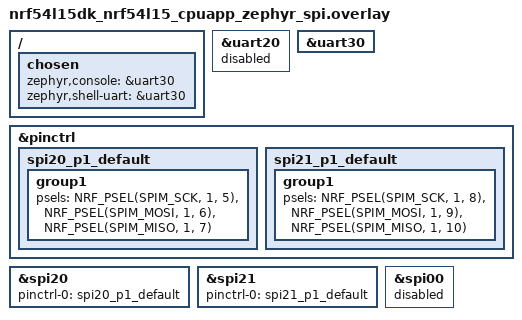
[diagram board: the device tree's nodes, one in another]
/*
 * Zephyr SPI test overlay: use Zephyr SPI driver on spi20 with P1.05 SCK, P1.06 MOSI.
 * Use with: west build -- -DCONF_FILE="prj.conf;prj_zephyr_spi.conf" -DDTC_OVERLAY_FILE=boards/nrf54l15dk_nrf54l15_cpuapp_zephyr_spi.overlay
 * Revert to nrfx by building without this overlay and without prj_zephyr_spi.conf.
 *
 * Slot 20: only one of SPI20/UARTE20/TWI20 can be enabled. Disable UART20 so SPI20 can be used.
 * Console was &uart20; point it to &uart30 so printk/console still work.
 */
/ {
	chosen {
		zephyr,console = &uart30;
		zephyr,shell-uart = &uart30;
	};
};

&uart20 {
	status = "disabled";
};

&uart30 {
	status = "okay";
};

&pinctrl {
	spi20_p1_default: spi20_p1_default {
		group1 {
			psels = <NRF_PSEL(SPIM_SCK, 1, 5)>,
				<NRF_PSEL(SPIM_MOSI, 1, 6)>,
				<NRF_PSEL(SPIM_MISO, 1, 7)>;
		};
	};

	spi21_p1_default: spi21_p1_default {
		group1 {
			/* Second SPI instance test on different P1 pins. */
			psels = <NRF_PSEL(SPIM_SCK, 1, 8)>,
				<NRF_PSEL(SPIM_MOSI, 1, 9)>,
				<NRF_PSEL(SPIM_MISO, 1, 10)>;
		};
	};
};

&spi20 {
	status = "okay";
	pinctrl-0 = <&spi20_p1_default>;
	pinctrl-names = "default";
};

&spi21 {
	status = "okay";
	pinctrl-0 = <&spi21_p1_default>;
	pinctrl-names = "default";
};

/* Slot 00: avoid conflict if app.overlay enables uart00; ensure only one of spi00/uart00. */
&spi00 {
	status = "disabled";
};
